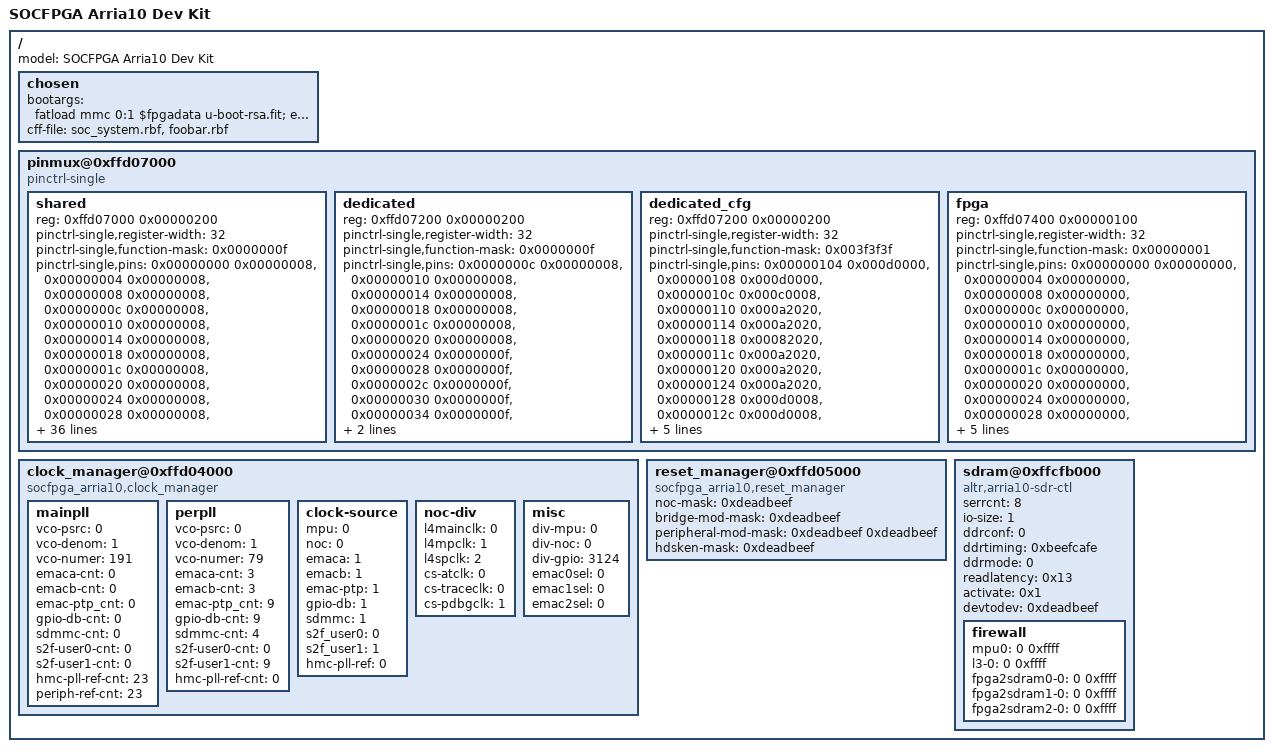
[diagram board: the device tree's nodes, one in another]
/*
 * Copyright (C) 2014 Altera Corporation <www.altera.com>
 *
 * SPDX-License-Identifier:	GPL-2.0+
 */

/dts-v1/;

/ {
	model = "SOCFPGA Arria10 Dev Kit";


	chosen {
		bootargs = "fatload mmc 0:1 $fpgadata u-boot-rsa.fit; \
			echo Checking image; \
			iminfo $fpgadata; \
			echo Boot the image; \
			bootm $fpgadata";
		cff-file = "soc_system.rbf", "foobar.rbf";
	};

	pinmux@0xffd07000 {
		#address-cells = <1>;
		#size-cells = <1>;
		compatible = "pinctrl-single";
		shared {
			reg = <0xffd07000 0x00000200>;
			pinctrl-single,register-width = <32>;
			pinctrl-single,function-mask = <0x0000000f>;
			pinctrl-single,pins =
				<0x00000000 0x00000008>,
				<0x00000004 0x00000008>,
				<0x00000008 0x00000008>,
				<0x0000000c 0x00000008>,
				<0x00000010 0x00000008>,
				<0x00000014 0x00000008>,
				<0x00000018 0x00000008>,
				<0x0000001c 0x00000008>,
				<0x00000020 0x00000008>,
				<0x00000024 0x00000008>,
				<0x00000028 0x00000008>,
				<0x0000002c 0x00000008>,
				<0x00000030 0x00000004>,
				<0x00000034 0x00000004>,
				<0x00000038 0x00000004>,
				<0x0000003c 0x00000004>,
				<0x00000040 0x00000004>,
				<0x00000044 0x00000004>,
				<0x00000048 0x00000004>,
				<0x0000004c 0x00000004>,
				<0x00000050 0x00000004>,
				<0x00000054 0x00000004>,
				<0x00000058 0x00000004>,
				<0x0000005c 0x00000004>,
				<0x00000060 0x00000003>,
				<0x00000064 0x00000003>,
				<0x00000068 0x00000003>,
				<0x0000006c 0x00000003>,
				<0x00000070 0x00000003>,
				<0x00000074 0x0000000f>,
				<0x00000078 0x0000000d>,
				<0x0000007c 0x0000000d>,
				<0x00000080 0x0000000f>,
				<0x00000084 0x0000000f>,
				<0x00000088 0x0000000f>,
				<0x0000008c 0x0000000f>,
				<0x00000090 0x00000000>,
				<0x00000094 0x00000000>,
				<0x00000098 0x0000000f>,
				<0x0000009c 0x0000000c>,
				<0x000000a0 0x0000000f>,
				<0x000000a4 0x0000000f>,
				<0x000000a8 0x0000000f>,
				<0x000000ac 0x0000000f>,
				<0x000000b0 0x0000000c>,
				<0x000000b4 0x0000000c>,
				<0x000000b8 0x0000000c>,
				<0x000000bc 0x0000000c>;

		};

		dedicated {
			reg = <0xffd07200 0x00000200>;
			pinctrl-single,register-width = <32>;
			pinctrl-single,function-mask = <0x0000000f>;
			pinctrl-single,pins =
				<0x0000000c 0x00000008>,
				<0x00000010 0x00000008>,
				<0x00000014 0x00000008>,
				<0x00000018 0x00000008>,
				<0x0000001c 0x00000008>,
				<0x00000020 0x00000008>,
				<0x00000024 0x0000000f>,
				<0x00000028 0x0000000f>,
				<0x0000002c 0x0000000f>,
				<0x00000030 0x0000000f>,
				<0x00000034 0x0000000f>,
				<0x00000038 0x0000000f>,
				<0x0000003c 0x0000000f>,
				<0x00000040 0x0000000f>;

		};
		
		dedicated_cfg {
			reg = <0xffd07200 0x00000200>;
			pinctrl-single,register-width = <32>;
			pinctrl-single,function-mask = <0x003f3f3f>;
			pinctrl-single,pins =
				<0x00000104 0x000d0000>,
				<0x00000108 0x000d0000>,
				<0x0000010c 0x000c0008>,
				<0x00000110 0x000a2020>,
				<0x00000114 0x000a2020>,
				<0x00000118 0x00082020>,
				<0x0000011c 0x000a2020>,
				<0x00000120 0x000a2020>,
				<0x00000124 0x000a2020>,
				<0x00000128 0x000d0008>,
				<0x0000012c 0x000d0008>,
				<0x00000130 0x000d0008>,
				<0x00000134 0x000d0008>,
				<0x00000138 0x000d0008>,
				<0x0000013c 0x000d0008>,
				<0x00000140 0x000d0008>,
				<0x00000144 0x000d0008>;

		};
		
		fpga {
			reg = <0xffd07400 0x00000100>;
			pinctrl-single,register-width = <32>;
			pinctrl-single,function-mask = <0x00000001>;
			pinctrl-single,pins =
				<0x00000000 0x00000000>,
				<0x00000004 0x00000000>,
				<0x00000008 0x00000000>,
				<0x0000000c 0x00000000>,
				<0x00000010 0x00000000>,
				<0x00000014 0x00000000>,
				<0x00000018 0x00000000>,
				<0x0000001c 0x00000000>,
				<0x00000020 0x00000000>,
				<0x00000024 0x00000000>,
				<0x00000028 0x00000000>,
				<0x0000002c 0x00000000>,
				<0x00000030 0x00000000>,
				<0x00000034 0x00000000>,
				<0x00000038 0x00000000>,
				<0x0000003c 0x00000000>,
				<0x00000040 0x00000000>;

		};

	};

	clock_manager@0xffd04000 {
		compatible = "socfpga_arria10,clock_manager";
		mainpll {
			vco-psrc = <0>;
			vco-denom = <1>;
			vco-numer = <191>;
			emaca-cnt = <0>;
			emacb-cnt = <0>;
			emac-ptp_cnt = <0>;
			gpio-db-cnt = <0>;
			sdmmc-cnt = <0>;
			s2f-user0-cnt = <0>;
			s2f-user1-cnt = <0>;
			hmc-pll-ref-cnt = <23>;
			periph-ref-cnt = <23>;
		};
		perpll {
			vco-psrc = <0>;
			vco-denom = <1>;
			vco-numer = <79>;
			emaca-cnt = <3>;
			emacb-cnt = <3>;
			emac-ptp_cnt = <9>;
			gpio-db-cnt = <9>;
			sdmmc-cnt = <4>;
			s2f-user0-cnt = <0>;
			s2f-user1-cnt = <9>;
			hmc-pll-ref-cnt = <0>;
		};
		clock-source {
			mpu = <0>;
			noc = <0>;
			emaca = <1>;
			emacb = <1>;
			emac-ptp = <1>;
			gpio-db = <1>;
			sdmmc = <1>;
			s2f_user0 = <0>;
			s2f_user1 = <1>;
			hmc-pll-ref = <0>;
		};
		noc-div {
			l4mainclk = <0>;
			l4mpclk = <1>;
			l4spclk = <2>;
			cs-atclk = <0>;
			cs-traceclk = <0>;
			cs-pdbgclk = <1>;
		};
		misc {
			div-mpu = <0>;
			div-noc = <0>;
			div-gpio = <3124>;
			emac0sel = <0>;
			emac1sel = <0>;
			emac2sel = <0>;
		};
		/*
		Info for clock frequency
		CLK_OSC1_HZ		(25000000)
		CLK_INTOSC_HZ		(50000000)
		CLK_F2SOSC_HZ		(200000000)
		CLK_MAINVCO_HZ		(2400000000)
		CLK_PERVCO_HZ		(1000000000)
		CLK_MPU_HZ		(1200000000)
		CLK_EMAC0_HZ		(250000000)
		CLK_EMAC1_HZ		(250000000)
		CLK_EMAC2_HZ		(250000000)
		CLK_EMAC_PTP_HZ		(100000000)
		CLK_SDMMC_HZ		(200000000)
		CLK_GPIODB_HZ		(32000)
		CLK_L3_MAIN_HZ		(400000000)
		CLK_L4_MAIN_HZ		(400000000)
		CLK_L4_MP_HZ		(200000000)
		CLK_L4_SP_HZ		(100000000)
		CLK_HMC_PLL_REF_HZ	(100000000)
		CLK_S2F_USER0_HZ	(100000000)
		CLK_S2F_USER1_HZ	(100000000)
		CLK_CS_AT_HZ		(400000000)
		CLK_CS_TRACE_HZ		(400000000)
		CLK_CS_PDBG_HZ		(100000000)
		*/
	};

	reset_manager@0xffd05000 {
		compatible = "socfpga_arria10,reset_manager";
		/* 1 mean particular IP need to be kept under reset state */
		noc-mask = <0xdeadbeef>;
		bridge-mod-mask = <0xdeadbeef>;
		peripheral-mod-mask = <0xdeadbeef 0xdeadbeef>;
		hdsken-mask = <0xdeadbeef>;
	};

	sdram@0xffcfb000 {
		compatible = "altr,arria10-sdr-ctl";
		serrcnt = <8>;
		io-size = <1>;
		ddrconf = <0>;
		ddrtiming = <0xbeefcafe>;
		ddrmode = <0>;
		readlatency = <0x13>;
		activate = <0x1>;
		devtodev = <0xdeadbeef>;
		firewall {
			/* existance of property implies it is enabled */
			/* values are <start end> */
			mpu0 = <0 0xffff>;
			/* mpu1 disabled */
			/* mpu2 disabled */
			/* mpu3 disabled */
			l3-0 = <0 0xffff>;
			/* l3-1 disabled */
			/* l3-2 disabled */
			/* l3-3 disabled */
			/* l3-4 disabled */
			/* l3-5 disabled */
			/* l3-6 disabled */
			/* l3-7 disabled */
			fpga2sdram0-0 = <0 0xffff>;
			/* fpga2sdram0-1 disabled */
			/* fpga2sdram0-2 disabled */
			/* fpga2sdram0-3 disabled */
			fpga2sdram1-0 = <0 0xffff>;
			/* fpga2sdram1-1 disabled */
			/* fpga2sdram1-2 disabled */
			/* fpga2sdram1-3 disabled */
			fpga2sdram2-0 = <0 0xffff>;
			/* fpga2sdram2-1 disabled */
			/* fpga2sdram2-2 disabled */
			/* fpga2sdram2-3 disabled */
		};
	};
};
